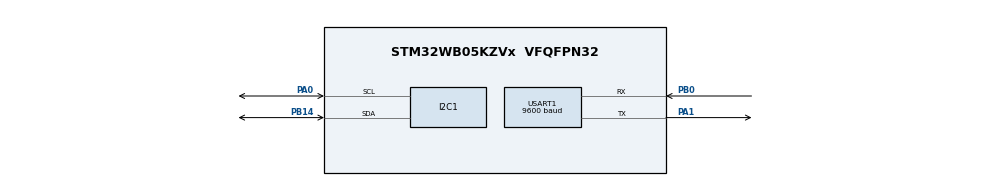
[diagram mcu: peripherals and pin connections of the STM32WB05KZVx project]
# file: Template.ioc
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Dma.Request0=USART1_RX
Dma.Request1=USART1_TX
Dma.USART1_RX.0.Direction=DMA_PERIPH_TO_MEMORY
Dma.USART1_RX.0.EventEnable=DISABLE
Dma.USART1_RX.0.FIFOMode=DMA_FIFOMODE_DISABLE
Dma.USART1_RX.0.Instance=DMA1_Channel5
Dma.USART1_RX.0.MDMA_Chaining=ENABLE
Dma.USART1_RX.0.Mandatory=DISABLE
Dma.USART1_RX.0.MemDataAlignment=DMA_MDATAALIGN_BYTE
Dma.USART1_RX.0.MemInc=DMA_MINC_ENABLE
Dma.USART1_RX.0.Mode=DMA_NORMAL
Dma.USART1_RX.0.PeriphDataAlignment=DMA_PDATAALIGN_BYTE
Dma.USART1_RX.0.PeriphInc=DMA_PINC_DISABLE
Dma.USART1_RX.0.Priority=DMA_PRIORITY_HIGH
Dma.USART1_RX.0.SignalID=NONE
Dma.USART1_RX.0.SyncEnable=DISABLE
Dma.USART1_RX.0.SyncRequestNumber=1
Dma.USART1_TX.1.Direction=DMA_MEMORY_TO_PERIPH
Dma.USART1_TX.1.EventEnable=DISABLE
Dma.USART1_TX.1.FIFOMode=DMA_FIFOMODE_DISABLE
Dma.USART1_TX.1.Instance=DMA1_Channel4
Dma.USART1_TX.1.MDMA_Chaining=ENABLE
Dma.USART1_TX.1.Mandatory=DISABLE
Dma.USART1_TX.1.MemDataAlignment=DMA_MDATAALIGN_BYTE
Dma.USART1_TX.1.MemInc=DMA_MINC_ENABLE
Dma.USART1_TX.1.Mode=DMA_NORMAL
Dma.USART1_TX.1.PeriphDataAlignment=DMA_PDATAALIGN_BYTE
Dma.USART1_TX.1.PeriphInc=DMA_PINC_DISABLE
Dma.USART1_TX.1.Priority=DMA_PRIORITY_LOW
Dma.USART1_TX.1.SignalID=NONE
Dma.USART1_TX.1.SyncEnable=DISABLE
Dma.USART1_TX.1.SyncRequestNumber=1
I2C1.Timing=0x00303D5B
Mcu.Family=STM32WB0
Mcu.Name=STM32WB05KZVx
Mcu.Package=VFQFPN32
NVIC.DMA_IRQn=true\:0\:0\:false\:false\:true\:true\:true\:true
NVIC.USART1_IRQn=true\:0\:0\:false\:false\:true\:true\:true\:true
OSCIN.Mode=HSE-External-Oscillator
OSCIN.Signal=RCC_OSC_IN
OSCOUT.Mode=HSE-External-Oscillator
OSCOUT.Signal=RCC_OSC_OUT
PA0.Mode=I2C
PA0.Signal=I2C1_SCL
PA1.GPIO_PuPd=GPIO_PULLUP
PA1.Mode=Asynchronous
PA1.Signal=USART1_TX
PB0.GPIO_PuPd=GPIO_PULLUP
PB0.Mode=Asynchronous
PB0.Signal=USART1_RX
PB14.Mode=I2C
PB14.Signal=I2C1_SDA
ProjectManager.HeapSize=0x000
ProjectManager.StackSize=0xC00
ProjectManager.TargetToolchain=CMake
RCC.HSE_VALUE=32000000
RCC.HSI_VALUE=64000000
RCC.LSE_Timout=100
RCC.LSE_VALUE=32768
RCC.RC64MPLLSource=RCC_LSCOSOURCE_PLL64
USART1.AutoBaudRateEnableParam=UART_ADVFEATURE_AUTOBAUDRATE_DISABLE
USART1.BaudRate=9600
USART1.DMADisableonRxErrorParam=ADVFEATURE_DMA_ENABLEONRXERROR
USART1.DataInvertParam=ADVFEATURE_DATAINV_DISABLE
USART1.MSBFirstParam=ADVFEATURE_MSBFIRST_DISABLE
USART1.Mode=MODE_TX_RX
USART1.OneBitSampling=UART_ONE_BIT_SAMPLE_DISABLE
USART1.OverSampling=UART_OVERSAMPLING_16
USART1.OverrunDisableParam=ADVFEATURE_OVERRUN_ENABLE
USART1.Parity=PARITY_ODD
USART1.RxPinLevelInvertParam=ADVFEATURE_RXINV_DISABLE
USART1.StopBits=STOPBITS_1
USART1.SwapParam=ADVFEATURE_SWAP_DISABLE
USART1.TxPinLevelInvertParam=ADVFEATURE_TXINV_DISABLE
USART1.VirtualMode-Asynchronous=VM_ASYNC
USART1.WordLength=WORDLENGTH_8B
VP_MEMORYMAP_VS_MEMORYMAP.Mode=CurAppReg
VP_PWR_VS_SECSignals.Mode=Security/Privilege
board=NUCLEO-WB05KZ

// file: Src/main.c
/* USER CODE BEGIN Header */
/**
 ******************************************************************************
 * @file    UART/UART_HyperTerminal_DMA/Src/main.c
 * @author  MCD Application Team
 * @brief   This sample code shows how to use UART HAL API to transmit
 *          and receive a data buffer with a communication process based on
 *          DMA transfer.
 *          The communication is done with the Hyperterminal PC application.
 ******************************************************************************
 * @attention
 *
 * Copyright (c) 2024 STMicroelectronics.
 * All rights reserved.
 *
 * This software is licensed under terms that can be found in the LICENSE file
 * in the root directory of this software component.
 * If no LICENSE file comes with this software, it is provided AS-IS.
 *
 ******************************************************************************
 */
/* USER CODE END Header */
#include "stm32wb0x_hal.h"
#include "stm32wb0x_nucleo.h"
#include "globals.h"
#include "utils/serial.h"
#include "app/app.h"

I2C_HandleTypeDef hi2c1;

UART_HandleTypeDef huart1;
DMA_HandleTypeDef hdma_usart1_rx;
DMA_HandleTypeDef hdma_usart1_tx;

void SystemClock_Config(void);
void PeriphCommonClock_Config(void);
static void MX_GPIO_Init(void);
static void MX_DMA_Init(void);
static void MX_USART1_UART_Init(void);
static void MX_I2C1_Init(void);

int main(void)
{

  /* USER CODE BEGIN 1 */

  /* STM32WB0x HAL library initialization:
       - Systick timer is configured by default as source of time base, but user
             can eventually implement his proper time base source (a general purpose
             timer for example or other time source), keeping in mind that Time base
             duration should be kept 1ms since PPP_TIMEOUT_VALUEs are defined and
             handled in milliseconds basis.
       - Set NVIC Group Priority to 4
       - Low Level Initialization
     */
  /* USER CODE END 1 */

  /* MCU Configuration--------------------------------------------------------*/

  /* Reset of all peripherals, Initializes the Flash interface and the Systick. */
  HAL_Init();

  /* Configure the system clock */
  SystemClock_Config();

  /* Configure the peripherals common clocks */
  PeriphCommonClock_Config();

  /* USER CODE BEGIN SysInit */
  /* Configure LD2 and LD3 */
  BSP_LED_Init(LD1);
  BSP_LED_Init(LD2);
  BSP_LED_Init(LD3);

  BSP_LED_Off(LD1);
  BSP_LED_Off(LD2);
  BSP_LED_Off(LD3);
  /* USER CODE END SysInit */

  /* Initialize all configured peripherals */
  MX_GPIO_Init();
  MX_DMA_Init();
  MX_USART1_UART_Init();
  Serial_Init(&huart1);
  MX_I2C1_Init();

#ifdef UNIT_TESTING
#include "utils/test_harness.h"
  extern TestCase test_cases[];
  extern int num_cases;

  Harness_Loop(test_cases, num_cases);
#else
  App();
#endif
}

void SystemClock_Config(void)
{
  RCC_OscInitTypeDef RCC_OscInitStruct = {0};
  RCC_ClkInitTypeDef RCC_ClkInitStruct = {0};

  /** Initializes the RCC Oscillators according to the specified parameters
   * in the RCC_OscInitTypeDef structure.
   */
  RCC_OscInitStruct.OscillatorType = RCC_OSCILLATORTYPE_HSE;
  RCC_OscInitStruct.HSEState = RCC_HSE_ON;
  if (HAL_RCC_OscConfig(&RCC_OscInitStruct) != HAL_OK)
  {
    Error_Handler();
  }

  /** Configure the SYSCLKSource and SYSCLKDivider
   */
  RCC_ClkInitStruct.SYSCLKSource = RCC_SYSCLKSOURCE_RC64MPLL;
  RCC_ClkInitStruct.SYSCLKDivider = RCC_RC64MPLL_DIV1;

  if (HAL_RCC_ClockConfig(&RCC_ClkInitStruct, FLASH_WAIT_STATES_1) != HAL_OK)
  {
    Error_Handler();
  }
}

void PeriphCommonClock_Config(void)
{
  RCC_PeriphCLKInitTypeDef PeriphClkInitStruct = {0};

  /** Initializes the peripherals clock
   */
  PeriphClkInitStruct.PeriphClockSelection = RCC_PERIPHCLK_SMPS;
  PeriphClkInitStruct.SmpsDivSelection = RCC_SMPSCLK_DIV4;

  if (HAL_RCCEx_PeriphCLKConfig(&PeriphClkInitStruct) != HAL_OK)
  {
    Error_Handler();
  }
}

static void MX_I2C1_Init(void)
{

  hi2c1.Instance = I2C1;
  hi2c1.Init.Timing = 0x00303D5B;
  hi2c1.Init.OwnAddress1 = 0;
  hi2c1.Init.AddressingMode = I2C_ADDRESSINGMODE_7BIT;
  hi2c1.Init.DualAddressMode = I2C_DUALADDRESS_DISABLE;
  hi2c1.Init.OwnAddress2 = 0;
  hi2c1.Init.OwnAddress2Masks = I2C_OA2_NOMASK;
  hi2c1.Init.GeneralCallMode = I2C_GENERALCALL_DISABLE;
  hi2c1.Init.NoStretchMode = I2C_NOSTRETCH_DISABLE;
  if (HAL_I2C_Init(&hi2c1) != HAL_OK)
  {
    Error_Handler();
  }

  /** Configure Analogue filter
   */
  if (HAL_I2CEx_ConfigAnalogFilter(&hi2c1, I2C_ANALOGFILTER_ENABLE) != HAL_OK)
  {
    Error_Handler();
  }

  /** Configure Digital filter
   */
  if (HAL_I2CEx_ConfigDigitalFilter(&hi2c1, 0) != HAL_OK)
  {
    Error_Handler();
  }
}

static void MX_USART1_UART_Init(void)
{

  huart1.Instance = USART1;
  huart1.Init.BaudRate = 115200;
  huart1.Init.WordLength = UART_WORDLENGTH_8B;
  huart1.Init.StopBits = UART_STOPBITS_1;
  huart1.Init.Parity = UART_PARITY_NONE;
  huart1.Init.Mode = UART_MODE_TX_RX;
  huart1.Init.HwFlowCtl = UART_HWCONTROL_NONE;
  huart1.Init.OverSampling = UART_OVERSAMPLING_16;
  huart1.Init.OneBitSampling = UART_ONE_BIT_SAMPLE_DISABLE;
  huart1.Init.ClockPrescaler = UART_PRESCALER_DIV1;
  huart1.AdvancedInit.AdvFeatureInit = UART_ADVFEATURE_NO_INIT;
  if (HAL_UART_Init(&huart1) != HAL_OK)
  {
    Error_Handler();
  }
  if (HAL_UARTEx_SetTxFifoThreshold(&huart1, UART_TXFIFO_THRESHOLD_1_8) != HAL_OK)
  {
    Error_Handler();
  }
  if (HAL_UARTEx_SetRxFifoThreshold(&huart1, UART_RXFIFO_THRESHOLD_1_8) != HAL_OK)
  {
    Error_Handler();
  }
  if (HAL_UARTEx_DisableFifoMode(&huart1) != HAL_OK)
  {
    Error_Handler();
  }
}

static void MX_DMA_Init(void)
{

  /* DMA controller clock enable */
  __HAL_RCC_DMA_CLK_ENABLE();

  /* DMA interrupt init */
  /* DMA_IRQn interrupt configuration */
  HAL_NVIC_SetPriority(DMA_IRQn, 0, 0);
  HAL_NVIC_EnableIRQ(DMA_IRQn);
}

static void MX_GPIO_Init(void)
{

  /* GPIO Ports Clock Enable */
  __HAL_RCC_GPIOB_CLK_ENABLE();
  __HAL_RCC_GPIOA_CLK_ENABLE();

}

/* USER CODE BEGIN 4 */

/**
 * @brief  Tx Transfer completed callback
 * @param  huart: UART handle.
 * @note   This example shows a simple way to report end of DMA Tx transfer, and
 *         you can add your own implementation.
 * @retval None
 */
void HAL_UART_TxCpltCallback(UART_HandleTypeDef *huart)
{
}

/**
 * @brief  Rx Transfer completed callback
 * @param  huart: UART handle
 * @note   This example shows a simple way to report end of DMA Rx transfer, and
 *         you can add your own implementation.
 * @retval None
 */
void HAL_UART_RxCpltCallback(UART_HandleTypeDef *huart)
{
}

/**
 * @brief  UART error callbacks
 * @param  huart: UART handle
 * @note   This example shows a simple way to report transfer error, and you can
 *         add your own implementation.
 * @retval None
 */
void HAL_UART_ErrorCallback(UART_HandleTypeDef *huart)
{
  /* Turn LD3 on: Transfer error in reception/transmission process */
  BSP_LED_On(LD3);
}

/* USER CODE END 4 */

void Error_Handler(void)
{
  /* USER CODE BEGIN Error_Handler_Debug */
  /* User can add his own implementation to report the HAL error return state */
  /* Turn LD3 on */
  BSP_LED_On(LD3);
  while (1)
    ;
  /* USER CODE END Error_Handler_Debug */
}

I2C_HandleTypeDef *get_i2c(void)
{
  return &hi2c1;
}

UART_HandleTypeDef *get_uart(void)
{
  return &huart1;
}
